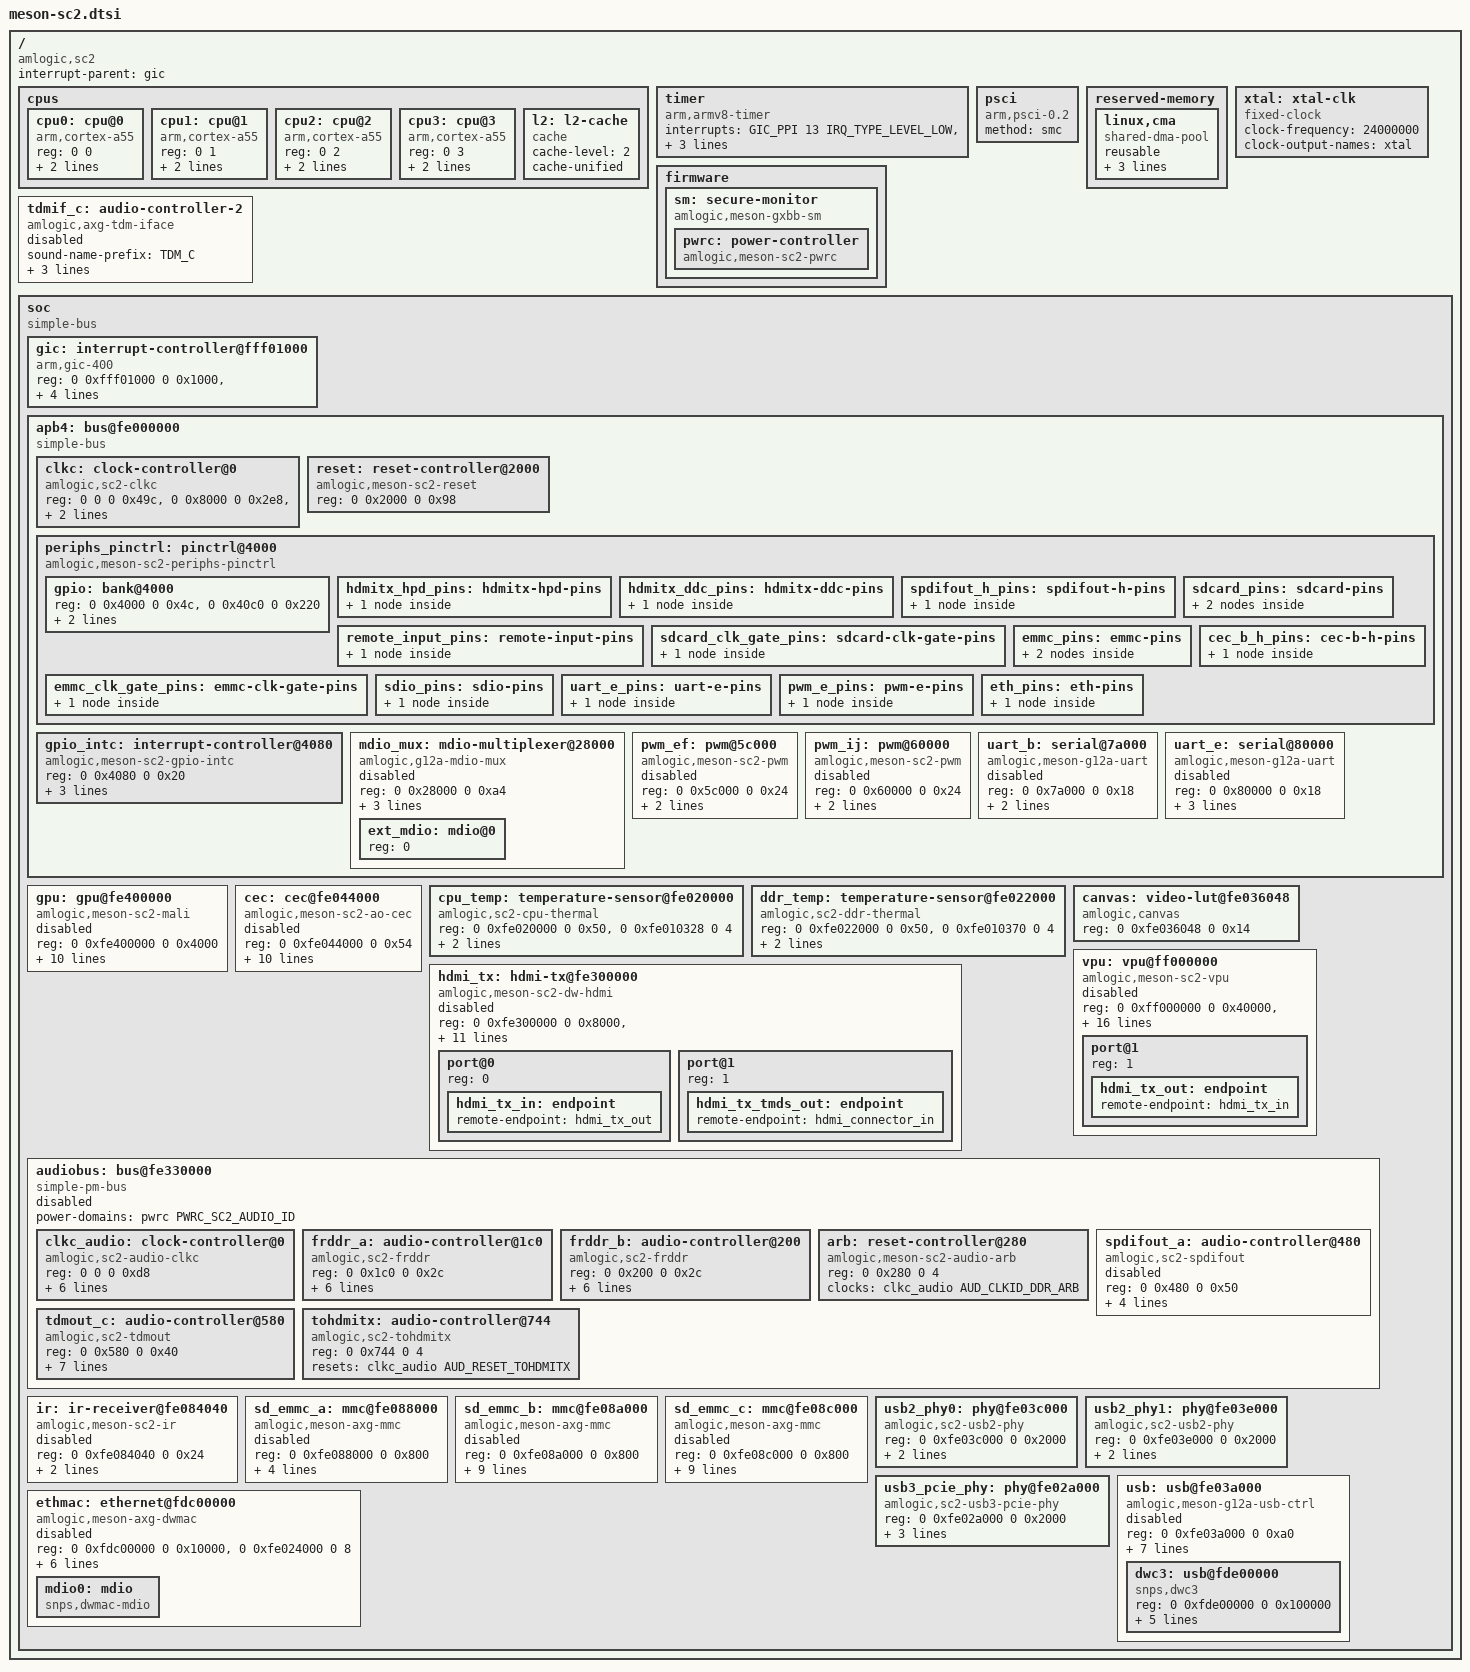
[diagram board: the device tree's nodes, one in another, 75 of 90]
// SPDX-License-Identifier: (GPL-2.0+ OR MIT)
/*
 * Amlogic SC2 minimal peripheral description.
 * Derived from Heiner Kallweit's SC2 tree (3730dc06ac), with register,
 * interrupt and pin data cross-checked against the original SC2 AH212 DT.
 * Copyright (c) 2019 Amlogic, Inc. All rights reserved.
 */
#include <dt-bindings/clock/amlogic,sc2-clkc.h>
#include <dt-bindings/clock/axg-audio-clkc.h>
#include <dt-bindings/gpio/gpio.h>
#include <dt-bindings/gpio/meson-sc2-gpio.h>
#include <dt-bindings/interrupt-controller/arm-gic.h>
#include <dt-bindings/interrupt-controller/irq.h>
#include <dt-bindings/phy/phy.h>
#include <dt-bindings/power/meson-sc2-power.h>
#include <dt-bindings/reset/amlogic,meson-sc2-reset.h>
#include <dt-bindings/reset/amlogic,meson-axg-audio-arb.h>
#include <dt-bindings/reset/amlogic,meson-g12a-audio-reset.h>
#include <dt-bindings/thermal/thermal.h>

/ {
	compatible = "amlogic,sc2";
	interrupt-parent = <&gic>;
	#address-cells = <2>;
	#size-cells = <2>;

	cpus {
		#address-cells = <2>;
		#size-cells = <0>;

		cpu0: cpu@0 {
			device_type = "cpu";
			compatible = "arm,cortex-a55";
			reg = <0 0>;
			enable-method = "psci";
			next-level-cache = <&l2>;
		};
		cpu1: cpu@1 {
			device_type = "cpu";
			compatible = "arm,cortex-a55";
			reg = <0 1>;
			enable-method = "psci";
			next-level-cache = <&l2>;
		};
		cpu2: cpu@2 {
			device_type = "cpu";
			compatible = "arm,cortex-a55";
			reg = <0 2>;
			enable-method = "psci";
			next-level-cache = <&l2>;
		};
		cpu3: cpu@3 {
			device_type = "cpu";
			compatible = "arm,cortex-a55";
			reg = <0 3>;
			enable-method = "psci";
			next-level-cache = <&l2>;
		};
		l2: l2-cache {
			compatible = "cache";
			cache-level = <2>;
			cache-unified;
		};
	};

	timer {
		compatible = "arm,armv8-timer";
		interrupts = <GIC_PPI 13 IRQ_TYPE_LEVEL_LOW>,
			     <GIC_PPI 14 IRQ_TYPE_LEVEL_LOW>,
			     <GIC_PPI 11 IRQ_TYPE_LEVEL_LOW>,
			     <GIC_PPI 10 IRQ_TYPE_LEVEL_LOW>;
	};

	psci {
		compatible = "arm,psci-0.2";
		method = "smc";
	};

	reserved-memory {
		#address-cells = <2>;
		#size-cells = <2>;
		ranges;

		linux,cma {
			compatible = "shared-dma-pool";
			reusable;
			size = <0x0 0x10000000>;
			alignment = <0x0 0x400000>;
			linux,cma-default;
		};
	};

	firmware {
		sm: secure-monitor {
			compatible = "amlogic,meson-gxbb-sm";

			pwrc: power-controller {
				compatible = "amlogic,meson-sc2-pwrc";
				#power-domain-cells = <1>;
			};
		};
	};

	xtal: xtal-clk {
		compatible = "fixed-clock";
		clock-frequency = <24000000>;
		clock-output-names = "xtal";
		#clock-cells = <0>;
	};

	tdmif_c: audio-controller-2 {
		compatible = "amlogic,axg-tdm-iface";
		#sound-dai-cells = <0>;
		sound-name-prefix = "TDM_C";
		clocks = <&clkc_audio AUD_CLKID_MST_C_SCLK>,
			 <&clkc_audio AUD_CLKID_MST_C_LRCLK>,
			 <&clkc_audio AUD_CLKID_MST_C_MCLK>;
		clock-names = "sclk", "lrclk", "mclk";
		status = "disabled";
	};

	soc {
		compatible = "simple-bus";
		#address-cells = <2>;
		#size-cells = <2>;
		ranges;

		gic: interrupt-controller@fff01000 {
			compatible = "arm,gic-400";
			reg = <0 0xfff01000 0 0x1000>,
			      <0 0xfff02000 0 0x2000>,
			      <0 0xfff04000 0 0x2000>,
			      <0 0xfff06000 0 0x2000>;
			interrupt-controller;
			#interrupt-cells = <3>;
			#address-cells = <0>;
			interrupts = <GIC_PPI 9 IRQ_TYPE_LEVEL_HIGH>;
		};

		apb4: bus@fe000000 {
			compatible = "simple-bus";
			#address-cells = <2>;
			#size-cells = <2>;
			ranges = <0 0 0 0xfe000000 0 0x480000>;

			clkc: clock-controller@0 {
				compatible = "amlogic,sc2-clkc";
				reg = <0 0 0 0x49c>, <0 0x8000 0 0x2e8>,
				      <0 0xe140 0 0x24>;
				reg-names = "basic", "pll", "cpu_clk";
				#clock-cells = <1>;
				clocks = <&xtal>;
				clock-names = "xtal";
			};

			reset: reset-controller@2000 {
				compatible = "amlogic,meson-sc2-reset", "amlogic,meson-s4-reset";
				reg = <0 0x2000 0 0x98>;
				#reset-cells = <1>;
			};

			periphs_pinctrl: pinctrl@4000 {
				compatible = "amlogic,meson-sc2-periphs-pinctrl";
				#address-cells = <2>;
				#size-cells = <2>;
				ranges;

				gpio: bank@4000 {
					reg = <0 0x4000 0 0x4c>, <0 0x40c0 0 0x220>;
					reg-names = "mux", "gpio";
					gpio-controller;
					#gpio-cells = <2>;
					gpio-ranges = <&periphs_pinctrl 0 0 87>;
				};
			};

			gpio_intc: interrupt-controller@4080 {
				compatible = "amlogic,meson-sc2-gpio-intc",
					     "amlogic,meson-gpio-intc";
				reg = <0 0x4080 0 0x20>;
				interrupt-controller;
				#interrupt-cells = <2>;
				#address-cells = <0>;
				amlogic,channel-interrupts =
					<10 11 12 13 14 15 16 17 18 19 20 21>;
			};

			mdio_mux: mdio-multiplexer@28000 {
				compatible = "amlogic,g12a-mdio-mux";
				reg = <0 0x28000 0 0xa4>;
				clocks = <&clkc CLKID_ETHPHY>, <&xtal>,
					 <&clkc CLKID_MPLL_50M>;
				clock-names = "pclk", "clkin0", "clkin1";
				mdio-parent-bus = <&mdio0>;
				#address-cells = <1>;
				#size-cells = <0>;
				status = "disabled";

				ext_mdio: mdio@0 {
					reg = <0>;
					#address-cells = <1>;
					#size-cells = <0>;
				};
			};

			pwm_ef: pwm@5c000 {
				compatible = "amlogic,meson-sc2-pwm", "amlogic,meson-s4-pwm";
				reg = <0 0x5c000 0 0x24>;
				clocks = <&clkc CLKID_PWM_E_GATE>, <&clkc CLKID_PWM_F_GATE>;
				#pwm-cells = <3>;
				status = "disabled";
			};

			pwm_ij: pwm@60000 {
				compatible = "amlogic,meson-sc2-pwm", "amlogic,meson-s4-pwm";
				reg = <0 0x60000 0 0x24>;
				clocks = <&clkc CLKID_PWM_I_GATE>, <&clkc CLKID_PWM_J_GATE>;
				#pwm-cells = <3>;
				status = "disabled";
			};

			uart_b: serial@7a000 {
				compatible = "amlogic,meson-g12a-uart",
					     "amlogic,meson-gx-uart",
					     "amlogic,meson-ao-uart";
				reg = <0 0x7a000 0 0x18>;
				interrupts = <GIC_SPI 169 IRQ_TYPE_EDGE_RISING>;
				clocks = <&xtal>, <&xtal>, <&xtal>;
				clock-names = "xtal", "pclk", "baud";
				status = "disabled";
			};

			uart_e: serial@80000 {
				compatible = "amlogic,meson-g12a-uart", "amlogic,meson-gx-uart";
				reg = <0 0x80000 0 0x18>;
				interrupts = <GIC_SPI 172 IRQ_TYPE_EDGE_RISING>;
				clocks = <&xtal>, <&clkc CLKID_UART_E>, <&xtal>;
				clock-names = "xtal", "pclk", "baud";
				fifo-size = <64>;
				status = "disabled";
			};
		};

		gpu: gpu@fe400000 {
			compatible = "amlogic,meson-sc2-mali", "arm,mali-bifrost";
			reg = <0 0xfe400000 0 0x4000>;
			interrupts = <GIC_SPI 146 IRQ_TYPE_LEVEL_HIGH>,
				     <GIC_SPI 145 IRQ_TYPE_LEVEL_HIGH>,
				     <GIC_SPI 144 IRQ_TYPE_LEVEL_HIGH>;
			interrupt-names = "job", "mmu", "gpu";
			clocks = <&clkc CLKID_MALI>;
			resets = <&reset RESET_MALI>, <&reset RESET_MALI_APB>;
			assigned-clocks = <&clkc CLKID_MALI_0_SEL>,
					  <&clkc CLKID_MALI_0>, <&clkc CLKID_MALI>;
			assigned-clock-parents = <&clkc CLKID_FCLK_DIV2P5>,
						 <0>, <&clkc CLKID_MALI_0>;
			assigned-clock-rates = <0>, <800000000>, <0>;
			status = "disabled";
		};

		cec: cec@fe044000 {
			compatible = "amlogic,meson-sc2-ao-cec";
			reg = <0 0xfe044000 0 0x54>;
			interrupts = <GIC_SPI 180 IRQ_TYPE_EDGE_RISING>;
			clocks = <&clkc CLKID_CECB_32K_CLKOUT>;
			clock-names = "core";
			assigned-clocks = <&clkc CLKID_CECB_32K_SEL_PRE>,
					  <&clkc CLKID_CECB_32K_SEL>,
					  <&clkc CLKID_CECB_32K_CLKOUT>;
			assigned-clock-parents = <&clkc CLKID_CECB_32K_DIV>,
						 <&clkc CLKID_CECB_32K_SEL_PRE>, <0>;
			assigned-clock-rates = <0>, <0>, <32768>;
			hdmi-phandle = <&hdmi_tx>;
			status = "disabled";
		};

		cpu_temp: temperature-sensor@fe020000 {
			compatible = "amlogic,sc2-cpu-thermal";
			reg = <0 0xfe020000 0 0x50>, <0 0xfe010328 0 4>;
			interrupts = <GIC_SPI 30 IRQ_TYPE_LEVEL_HIGH>;
			clocks = <&clkc CLKID_TS_CLK_GATE>;
			#thermal-sensor-cells = <0>;
		};

		ddr_temp: temperature-sensor@fe022000 {
			compatible = "amlogic,sc2-ddr-thermal";
			reg = <0 0xfe022000 0 0x50>, <0 0xfe010370 0 4>;
			interrupts = <GIC_SPI 31 IRQ_TYPE_LEVEL_HIGH>;
			clocks = <&clkc CLKID_TS_CLK_GATE>;
			#thermal-sensor-cells = <0>;
		};

		canvas: video-lut@fe036048 {
			compatible = "amlogic,canvas";
			reg = <0 0xfe036048 0 0x14>;
		};

		vpu: vpu@ff000000 {
			compatible = "amlogic,meson-sc2-vpu";
			reg = <0 0xff000000 0 0x40000>,
			      <0 0xfe000000 0 0x49c>,
			      <0 0xfe008000 0 0x400>,
			      <0 0xfe00c000 0 0x800>;
			reg-names = "vpu", "clkctrl", "anactrl", "pwrctrl";
			interrupts = <GIC_SPI 197 IRQ_TYPE_EDGE_RISING>;
			power-domains = <&pwrc PWRC_SC2_VPU_HDMI_ID>;
			clocks = <&clkc CLKID_VPU>, <&clkc CLKID_VAPB>,
				 <&clkc CLKID_VPU_INTR>;
			clock-names = "vpu", "vapb", "intr";
			assigned-clocks = <&clkc CLKID_VPU_0_MUX>, <&clkc CLKID_VPU_0>,
					  <&clkc CLKID_VPU>, <&clkc CLKID_VAPB_0_MUX>,
					  <&clkc CLKID_VAPB_0>, <&clkc CLKID_VAPB>;
			assigned-clock-parents = <&clkc CLKID_FCLK_DIV3>, <0>,
						 <&clkc CLKID_VPU_0>, <&clkc CLKID_FCLK_DIV4>,
						 <0>, <&clkc CLKID_VAPB_0>;
			assigned-clock-rates = <0>, <666666667>, <0>, <0>, <250000000>, <0>;
			amlogic,canvas = <&canvas>;
			#address-cells = <1>;
			#size-cells = <0>;
			status = "disabled";

			port@1 {
				reg = <1>;
				hdmi_tx_out: endpoint {
					remote-endpoint = <&hdmi_tx_in>;
				};
			};
		};

		hdmi_tx: hdmi-tx@fe300000 {
			compatible = "amlogic,meson-sc2-dw-hdmi";
			reg = <0 0xfe300000 0 0x8000>, <0 0xfe308000 0 0x8000>;
			reg-names = "dwc", "top";
			interrupts = <GIC_SPI 204 IRQ_TYPE_EDGE_RISING>;
			clocks = <&clkc CLKID_HDMI>, <&clkc CLKID_HDMITX_APB>,
				 <&clkc CLKID_CTS_ENCI>;
			clock-names = "isfr", "iahb", "venci";
			assigned-clocks = <&clkc CLKID_HDMI_MUX>, <&clkc CLKID_HDMI>;
			assigned-clock-parents = <&xtal>, <0>;
			assigned-clock-rates = <0>, <24000000>;
			resets = <&reset RESET_HDMITX_APB>, <&reset RESET_HDMI_TX>,
				 <&reset RESET_HDMITXPHY>, <&reset RESET_VID_PLL_DIV>;
			reset-names = "hdmitx_apb", "hdmitx", "hdmitx_phy", "vid_pll_div";
			#address-cells = <1>;
			#size-cells = <0>;
			#sound-dai-cells = <0>;
			status = "disabled";

			port@0 {
				reg = <0>;
				hdmi_tx_in: endpoint {
					remote-endpoint = <&hdmi_tx_out>;
				};
			};

			port@1 {
				reg = <1>;
				hdmi_tx_tmds_out: endpoint {
					remote-endpoint = <&hdmi_connector_in>;
				};
			};
		};

		audiobus: bus@fe330000 {
			compatible = "simple-pm-bus";
			#address-cells = <2>;
			#size-cells = <2>;
			ranges = <0 0 0 0xfe330000 0 0x3000>;
			power-domains = <&pwrc PWRC_SC2_AUDIO_ID>;
			status = "disabled";

			clkc_audio: clock-controller@0 {
				compatible = "amlogic,sc2-audio-clkc";
				reg = <0 0 0 0xd8>;
				#clock-cells = <1>;
				#reset-cells = <1>;
				clocks = <&clkc CLKID_AUDIO>, <&clkc CLKID_MPLL0>,
					 <&clkc CLKID_MPLL1>, <&clkc CLKID_MPLL2>,
					 <&clkc CLKID_MPLL3>, <&clkc CLKID_HIFI_PLL>,
					 <&clkc CLKID_FCLK_DIV3>, <&clkc CLKID_FCLK_DIV4>,
					 <&clkc CLKID_FCLK_DIV5>;
				clock-names = "pclk", "mst_in0", "mst_in1", "mst_in2",
					      "mst_in3", "mst_in4", "mst_in5", "mst_in6",
					      "mst_in7";
				resets = <&reset RESET_AUDIO>;
			};

			frddr_a: audio-controller@1c0 {
				compatible = "amlogic,sc2-frddr";
				reg = <0 0x1c0 0 0x2c>;
				#sound-dai-cells = <0>;
				sound-name-prefix = "FRDDR_A";
				interrupts = <GIC_SPI 36 IRQ_TYPE_EDGE_RISING>;
				clocks = <&clkc_audio AUD_CLKID_FRDDR_A>;
				resets = <&arb AXG_ARB_FRDDR_A>,
					 <&clkc_audio AUD_RESET_FRDDR_A>;
				reset-names = "arb", "rst";
				amlogic,fifo-depth = <1024>;
			};

			frddr_b: audio-controller@200 {
				compatible = "amlogic,sc2-frddr";
				reg = <0 0x200 0 0x2c>;
				#sound-dai-cells = <0>;
				sound-name-prefix = "FRDDR_B";
				interrupts = <GIC_SPI 37 IRQ_TYPE_EDGE_RISING>;
				clocks = <&clkc_audio AUD_CLKID_FRDDR_B>;
				resets = <&arb AXG_ARB_FRDDR_B>,
					 <&clkc_audio AUD_RESET_FRDDR_B>;
				reset-names = "arb", "rst";
				amlogic,fifo-depth = <1024>;
			};

			arb: reset-controller@280 {
				compatible = "amlogic,meson-sc2-audio-arb";
				reg = <0 0x280 0 4>;
				#reset-cells = <1>;
				clocks = <&clkc_audio AUD_CLKID_DDR_ARB>;
			};

			spdifout_a: audio-controller@480 {
				compatible = "amlogic,sc2-spdifout";
				reg = <0 0x480 0 0x50>;
				#sound-dai-cells = <0>;
				sound-name-prefix = "SPDIFOUT_A";
				clocks = <&clkc_audio AUD_CLKID_SPDIFOUT>,
					 <&clkc_audio AUD_CLKID_SPDIFOUT_CLK>;
				clock-names = "pclk", "mclk";
				resets = <&clkc_audio AUD_RESET_SPDIFOUT>;
				status = "disabled";
			};

			tdmout_c: audio-controller@580 {
				compatible = "amlogic,sc2-tdmout";
				reg = <0 0x580 0 0x40>;
				sound-name-prefix = "TDMOUT_C";
				resets = <&clkc_audio AUD_RESET_TDMOUT_C>;
				clocks = <&clkc_audio AUD_CLKID_TDMOUT_C>,
					 <&clkc_audio AUD_CLKID_TDMOUT_C_SCLK>,
					 <&clkc_audio AUD_CLKID_TDMOUT_C_SCLK_SEL>,
					 <&clkc_audio AUD_CLKID_TDMOUT_C_LRCLK>,
					 <&clkc_audio AUD_CLKID_TDMOUT_C_LRCLK>;
				clock-names = "pclk", "sclk", "sclk_sel", "lrclk",
					      "lrclk_sel";
			};

			tohdmitx: audio-controller@744 {
				compatible = "amlogic,sc2-tohdmitx";
				reg = <0 0x744 0 4>;
				#sound-dai-cells = <1>;
				resets = <&clkc_audio AUD_RESET_TOHDMITX>;
			};
		};

		ir: ir-receiver@fe084040 {
			compatible = "amlogic,meson-sc2-ir", "amlogic,meson-gxbb-ir";
			reg = <0 0xfe084040 0 0x24>;
			interrupts = <GIC_SPI 22 IRQ_TYPE_EDGE_RISING>;
			clocks = <&clkc CLKID_IR_CTRL>;
			status = "disabled";
		};

		sd_emmc_a: mmc@fe088000 {
			compatible = "amlogic,meson-axg-mmc";
			reg = <0 0xfe088000 0 0x800>;
			interrupts = <GIC_SPI 176 IRQ_TYPE_LEVEL_HIGH>;
			clocks = <&clkc CLKID_SD_EMMC_A>, <&xtal>,
				 <&clkc CLKID_FCLK_DIV2>;
			clock-names = "core", "clkin0", "clkin1";
			resets = <&reset RESET_SD_EMMC_A>;
			#address-cells = <1>;
			#size-cells = <0>;
			status = "disabled";
		};

		sd_emmc_b: mmc@fe08a000 {
			compatible = "amlogic,meson-axg-mmc";
			reg = <0 0xfe08a000 0 0x800>;
			interrupts = <GIC_SPI 177 IRQ_TYPE_EDGE_RISING>;
			clocks = <&clkc CLKID_SD_EMMC_B>,
				 <&clkc CLKID_SD_EMMC_B_CLK>, <&clkc CLKID_FCLK_DIV2>;
			clock-names = "core", "clkin0", "clkin1";
			/* Initial identification needs the 24MHz parent, not fclk. */
			assigned-clocks = <&clkc CLKID_SD_EMMC_B_CLK_MUX>,
					  <&clkc CLKID_SD_EMMC_B_CLK>;
			assigned-clock-parents = <&xtal>;
			assigned-clock-rates = <0>, <24000000>;
			resets = <&reset RESET_SD_EMMC_B>;
			status = "disabled";
		};

		sd_emmc_c: mmc@fe08c000 {
			compatible = "amlogic,meson-axg-mmc";
			reg = <0 0xfe08c000 0 0x800>;
			interrupts = <GIC_SPI 178 IRQ_TYPE_EDGE_RISING>;
			clocks = <&clkc CLKID_NAND>,
				 <&clkc CLKID_SD_EMMC_C_CLK>, <&clkc CLKID_FCLK_DIV2>;
			clock-names = "core", "clkin0", "clkin1";
			assigned-clocks = <&clkc CLKID_SD_EMMC_C_CLK_MUX>,
					  <&clkc CLKID_SD_EMMC_C_CLK>;
			assigned-clock-parents = <&xtal>;
			assigned-clock-rates = <0>, <24000000>;
			resets = <&reset RESET_NAND_EMMC>;
			status = "disabled";
		};

		usb2_phy0: phy@fe03c000 {
			compatible = "amlogic,sc2-usb2-phy";
			reg = <0 0xfe03c000 0 0x2000>;
			clocks = <&xtal>;
			clock-names = "xtal";
			resets = <&reset RESET_USBPHY20>;
			reset-names = "phy";
			#phy-cells = <0>;
		};

		usb2_phy1: phy@fe03e000 {
			compatible = "amlogic,sc2-usb2-phy";
			reg = <0 0xfe03e000 0 0x2000>;
			clocks = <&xtal>;
			clock-names = "xtal";
			resets = <&reset RESET_USBPHY21>;
			reset-names = "phy";
			#phy-cells = <0>;
		};

		usb3_pcie_phy: phy@fe02a000 {
			compatible = "amlogic,sc2-usb3-pcie-phy";
			reg = <0 0xfe02a000 0 0x2000>;
			clocks = <&clkc CLKID_PCIE_PLL>, <&clkc CLKID_PCIE_BGP>;
			clock-names = "ref_clk", "bgp";
			resets = <&reset RESET_PCIE_PHY>;
			reset-names = "phy";
			#phy-cells = <1>;
		};

		usb: usb@fe03a000 {
			compatible = "amlogic,meson-g12a-usb-ctrl";
			reg = <0 0xfe03a000 0 0xa0>;
			interrupts = <GIC_SPI 129 IRQ_TYPE_LEVEL_HIGH>;
			#address-cells = <2>;
			#size-cells = <2>;
			ranges;
			clocks = <&clkc CLKID_USB>;
			resets = <&reset RESET_USBCTRL>;
			power-domains = <&pwrc PWRC_SC2_USB_COMB_ID>;
			phys = <&usb2_phy0>, <&usb2_phy1>,
			       <&usb3_pcie_phy PHY_TYPE_USB3>;
			phy-names = "usb2-phy0", "usb2-phy1", "usb3-phy0";
			dr_mode = "host";
			status = "disabled";

			dwc3: usb@fde00000 {
				compatible = "snps,dwc3";
				reg = <0 0xfde00000 0 0x100000>;
				interrupts = <GIC_SPI 130 IRQ_TYPE_LEVEL_HIGH>;
				dr_mode = "host";
				snps,dis_u2_susphy_quirk;
				snps,quirk-frame-length-adjustment = <0x20>;
				snps,parkmode-disable-ss-quirk;
			};
		};

		ethmac: ethernet@fdc00000 {
			compatible = "amlogic,meson-axg-dwmac", "snps,dwmac-3.70a",
				     "snps,dwmac";
			reg = <0 0xfdc00000 0 0x10000>, <0 0xfe024000 0 8>;
			interrupts = <GIC_SPI 74 IRQ_TYPE_LEVEL_HIGH>;
			interrupt-names = "macirq";
			clocks = <&clkc CLKID_ETH>, <&clkc CLKID_FCLK_DIV2>,
				 <&clkc CLKID_MPLL2>;
			clock-names = "stmmaceth", "clkin0", "clkin1";
			power-domains = <&pwrc PWRC_SC2_ETH_ID>;
			rx-fifo-depth = <4096>;
			tx-fifo-depth = <2048>;
			status = "disabled";

			mdio0: mdio {
				compatible = "snps,dwmac-mdio";
				#address-cells = <1>;
				#size-cells = <0>;
			};
		};
	};
};

&periphs_pinctrl {
	hdmitx_hpd_pins: hdmitx-hpd-pins {
		mux {
			groups = "hdmitx_hpd_in";
			function = "hdmitx";
			bias-disable;
		};
	};

	hdmitx_ddc_pins: hdmitx-ddc-pins {
		mux {
			groups = "hdmitx_sda", "hdmitx_sck";
			function = "hdmitx";
			bias-disable;
			drive-strength-microamp = <3000>;
		};
	};

	spdifout_h_pins: spdifout-h-pins {
		mux {
			groups = "spdif_out_h";
			function = "spdif_out";
			bias-disable;
		};
	};

	remote_input_pins: remote-input-pins {
		mux {
			groups = "remote_input_d5";
			function = "remote_input";
			bias-disable;
		};
	};

	sdcard_pins: sdcard-pins {
		mux {
			groups = "sdcard_d0_c", "sdcard_d1_c", "sdcard_d2_c",
				 "sdcard_d3_c", "sdcard_cmd_c", "sdcard_clk_c";
			function = "sdcard";
			bias-pull-up;
			drive-strength-microamp = <4000>;
		};

		cd {
			groups = "GPIOC_6";
			function = "gpio_periphs";
			bias-pull-up;
			input-enable;
		};
	};

	sdcard_clk_gate_pins: sdcard-clk-gate-pins {
		mux {
			groups = "GPIOC_4";
			function = "gpio_periphs";
			bias-pull-down;
			drive-strength-microamp = <4000>;
		};
	};

	emmc_pins: emmc-pins {
		data-cmd {
			groups = "emmc_nand_d0", "emmc_nand_d1", "emmc_nand_d2",
				 "emmc_nand_d3", "emmc_nand_d4", "emmc_nand_d5",
				 "emmc_nand_d6", "emmc_nand_d7", "emmc_cmd";
			function = "emmc";
			bias-pull-up;
			drive-strength-microamp = <4000>;
		};

		clk {
			groups = "emmc_clk";
			function = "emmc";
			bias-disable;
			drive-strength-microamp = <4000>;
		};
	};

	emmc_clk_gate_pins: emmc-clk-gate-pins {
		mux {
			groups = "GPIOB_8";
			function = "gpio_periphs";
			bias-pull-down;
			drive-strength-microamp = <4000>;
		};
	};

	cec_b_h_pins: cec-b-h-pins {
		mux {
			groups = "cec_b_h";
			function = "cec_b";
			bias-disable;
		};
	};

	sdio_pins: sdio-pins {
		mux {
			groups = "sdio_d0_x", "sdio_d1_x", "sdio_d2_x", "sdio_d3_x",
				 "sdio_clk_x", "sdio_cmd_x";
			function = "sdio";
			bias-disable;
			drive-strength-microamp = <4000>;
		};
	};

	uart_e_pins: uart-e-pins {
		mux {
			groups = "uart_e_tx", "uart_e_rx", "uart_e_cts", "uart_e_rts";
			function = "uart_e";
			bias-pull-up;
		};
	};

	pwm_e_pins: pwm-e-pins {
		mux {
			groups = "pwm_e";
			function = "pwm_e";
			bias-disable;
			drive-strength-microamp = <500>;
		};
	};

	eth_pins: eth-pins {
		mux {
			groups = "eth_mdio", "eth_mdc", "eth_rgmii_rx_clk",
				 "eth_rx_dv", "eth_rxd0", "eth_rxd1", "eth_txen",
				 "eth_txd0", "eth_txd1", "eth_rxd2_rgmii",
				 "eth_rxd3_rgmii", "eth_rgmii_tx_clk",
				 "eth_txd2_rgmii", "eth_txd3_rgmii";
			function = "eth";
			drive-strength-microamp = <4000>;
			bias-disable;
		};
	};
};
